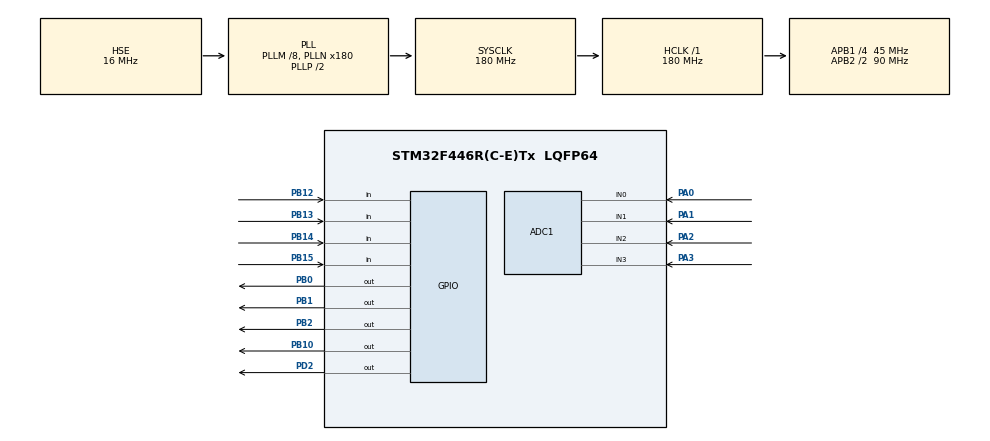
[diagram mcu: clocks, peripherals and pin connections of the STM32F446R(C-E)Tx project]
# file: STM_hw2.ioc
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ADC1.Channel-0\#ChannelRegularConversion=ADC_CHANNEL_0
ADC1.Channel-1\#ChannelRegularConversion=ADC_CHANNEL_1
ADC1.Channel-2\#ChannelRegularConversion=ADC_CHANNEL_2
ADC1.Channel-3\#ChannelRegularConversion=ADC_CHANNEL_3
ADC1.DMAContinuousRequests=ENABLE
ADC1.ExternalTrigConv=ADC_EXTERNALTRIGCONV_T8_TRGO
ADC1.NbrOfConversion=4
ADC1.NbrOfConversionFlag=1
ADC1.Rank-0\#ChannelRegularConversion=1
ADC1.Rank-1\#ChannelRegularConversion=2
ADC1.Rank-2\#ChannelRegularConversion=3
ADC1.Rank-3\#ChannelRegularConversion=4
ADC1.SamplingTime-0\#ChannelRegularConversion=ADC_SAMPLETIME_15CYCLES
ADC1.SamplingTime-1\#ChannelRegularConversion=ADC_SAMPLETIME_15CYCLES
ADC1.SamplingTime-2\#ChannelRegularConversion=ADC_SAMPLETIME_15CYCLES
ADC1.SamplingTime-3\#ChannelRegularConversion=ADC_SAMPLETIME_15CYCLES
ADC1.ScanConvMode=ENABLE
ADC1.master=1
Dma.ADC1.0.Direction=DMA_PERIPH_TO_MEMORY
Dma.ADC1.0.FIFOMode=DMA_FIFOMODE_DISABLE
Dma.ADC1.0.Instance=DMA2_Stream0
Dma.ADC1.0.MemDataAlignment=DMA_MDATAALIGN_WORD
Dma.ADC1.0.MemInc=DMA_MINC_ENABLE
Dma.ADC1.0.Mode=DMA_CIRCULAR
Dma.ADC1.0.PeriphDataAlignment=DMA_PDATAALIGN_WORD
Dma.ADC1.0.PeriphInc=DMA_PINC_DISABLE
Dma.ADC1.0.Priority=DMA_PRIORITY_LOW
Dma.Request0=ADC1
Mcu.Family=STM32F4
Mcu.Name=STM32F446R(C-E)Tx
Mcu.Package=LQFP64
NVIC.ADC_IRQn=true\:0\:0\:false\:false\:true\:true\:true\:true
NVIC.DMA2_Stream0_IRQn=true\:0\:0\:false\:false\:true\:false\:true\:true
NVIC.PriorityGroup=NVIC_PRIORITYGROUP_4
NVIC.TIM8_UP_TIM13_IRQn=true\:0\:0\:false\:false\:true\:true\:true\:true
PA0-WKUP.Signal=ADCx_IN0
PA1.Signal=ADCx_IN1
PA13.Mode=Serial_Wire
PA13.Signal=SYS_JTMS-SWDIO
PA14.Mode=Serial_Wire
PA14.Signal=SYS_JTCK-SWCLK
PA2.Signal=ADCx_IN2
PA3.Signal=ADCx_IN3
PB0.Signal=GPIO_Output
PB1.Signal=GPIO_Output
PB10.Signal=GPIO_Output
PB12.Signal=GPIO_Input
PB13.Signal=GPIO_Input
PB14.Signal=GPIO_Input
PB15.Signal=GPIO_Input
PB2.Signal=GPIO_Output
PD2.Signal=GPIO_Output
PH0-OSC_IN.Mode=HSE-External-Oscillator
PH0-OSC_IN.Signal=RCC_OSC_IN
PH1-OSC_OUT.Mode=HSE-External-Oscillator
PH1-OSC_OUT.Signal=RCC_OSC_OUT
ProjectManager.HeapSize=0x200
ProjectManager.StackSize=0x400
ProjectManager.TargetToolchain=STM32CubeIDE
RCC.AHBFreq_Value=180000000
RCC.APB1CLKDivider=RCC_HCLK_DIV4
RCC.APB1Freq_Value=45000000
RCC.APB1TimFreq_Value=90000000
RCC.APB2CLKDivider=RCC_HCLK_DIV2
RCC.APB2Freq_Value=90000000
RCC.APB2TimFreq_Value=180000000
RCC.CortexFreq_Value=180000000
RCC.HCLKFreq_Value=180000000
RCC.HSE_VALUE=16000000
RCC.PLLM=8
RCC.PLLN=180
RCC.PLLSourceVirtual=RCC_PLLSOURCE_HSE
RCC.SYSCLKFreq_VALUE=180000000
RCC.SYSCLKSource=RCC_SYSCLKSOURCE_PLLCLK
RCC.USBFreq_Value=180000000
RCC.VCOOutputFreq_Value=360000000
SH.ADCx_IN0.0=ADC1_IN0,IN0
SH.ADCx_IN1.0=ADC1_IN1,IN1
SH.ADCx_IN2.0=ADC1_IN2,IN2
SH.ADCx_IN3.0=ADC1_IN3,IN3
TIM8.Period=10000-1
TIM8.Prescaler=180-1
TIM8.TIM_MasterOutputTrigger=TIM_TRGO_UPDATE
VP_TIM8_VS_ClockSourceINT.Mode=Internal
board=custom

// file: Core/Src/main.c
/* USER CODE BEGIN Header */
/**
  ******************************************************************************
  * @file           : main.c
  * @brief          : Main program body
  ******************************************************************************
  * @attention
  *
  * Copyright (c) 2026 STMicroelectronics.
  * All rights reserved.
  *
  * This software is licensed under terms that can be found in the LICENSE file
  * in the root directory of this software component.
  * If no LICENSE file comes with this software, it is provided AS-IS.
  *
  ******************************************************************************
  */
/* USER CODE END Header */
#include "main.h"

/* USER CODE BEGIN Includes */
#include "hw2.h"
/* USER CODE END Includes */

ADC_HandleTypeDef hadc1;
DMA_HandleTypeDef hdma_adc1;

TIM_HandleTypeDef htim8;

/* USER CODE BEGIN PV */
uint32_t adc1_buffer[4] = {0, };
volatile uint8_t adc_updated_flag = 0;
/* USER CODE END PV */

void SystemClock_Config(void);
static void MX_GPIO_Init(void);
static void MX_DMA_Init(void);
static void MX_ADC1_Init(void);
static void MX_TIM8_Init(void);

int main(void)
{

  /* MCU Configuration--------------------------------------------------------*/

  /* Reset of all peripherals, Initializes the Flash interface and the Systick. */
  HAL_Init();

  /* Configure the system clock */
  SystemClock_Config();

  /* Initialize all configured peripherals */
  MX_GPIO_Init();
  MX_DMA_Init();
  MX_ADC1_Init();
  MX_TIM8_Init();
  /* USER CODE BEGIN 2 */
  HAL_TIM_Base_Start_IT(&htim8);
  HAL_ADC_Start_DMA(&hadc1, adc1_buffer, 4);
  hw2_init();
  /* USER CODE END 2 */

  /* Infinite loop */
  while (1)
  {

    /* USER CODE BEGIN 3 */
    hw2_loop();
  }
  /* USER CODE END 3 */
}

void SystemClock_Config(void)
{
  RCC_OscInitTypeDef RCC_OscInitStruct = {0};
  RCC_ClkInitTypeDef RCC_ClkInitStruct = {0};

  /** Configure the main internal regulator output voltage
  */
  __HAL_RCC_PWR_CLK_ENABLE();
  __HAL_PWR_VOLTAGESCALING_CONFIG(PWR_REGULATOR_VOLTAGE_SCALE1);

  /** Initializes the RCC Oscillators according to the specified parameters
  * in the RCC_OscInitTypeDef structure.
  */
  RCC_OscInitStruct.OscillatorType = RCC_OSCILLATORTYPE_HSE;
  RCC_OscInitStruct.HSEState = RCC_HSE_ON;
  RCC_OscInitStruct.PLL.PLLState = RCC_PLL_ON;
  RCC_OscInitStruct.PLL.PLLSource = RCC_PLLSOURCE_HSE;
  RCC_OscInitStruct.PLL.PLLM = 8;
  RCC_OscInitStruct.PLL.PLLN = 180;
  RCC_OscInitStruct.PLL.PLLP = RCC_PLLP_DIV2;
  RCC_OscInitStruct.PLL.PLLQ = 2;
  RCC_OscInitStruct.PLL.PLLR = 2;
  if (HAL_RCC_OscConfig(&RCC_OscInitStruct) != HAL_OK)
  {
    Error_Handler();
  }

  /** Activate the Over-Drive mode
  */
  if (HAL_PWREx_EnableOverDrive() != HAL_OK)
  {
    Error_Handler();
  }

  /** Initializes the CPU, AHB and APB buses clocks
  */
  RCC_ClkInitStruct.ClockType = RCC_CLOCKTYPE_HCLK|RCC_CLOCKTYPE_SYSCLK
                              |RCC_CLOCKTYPE_PCLK1|RCC_CLOCKTYPE_PCLK2;
  RCC_ClkInitStruct.SYSCLKSource = RCC_SYSCLKSOURCE_PLLCLK;
  RCC_ClkInitStruct.AHBCLKDivider = RCC_SYSCLK_DIV1;
  RCC_ClkInitStruct.APB1CLKDivider = RCC_HCLK_DIV4;
  RCC_ClkInitStruct.APB2CLKDivider = RCC_HCLK_DIV2;

  if (HAL_RCC_ClockConfig(&RCC_ClkInitStruct, FLASH_LATENCY_5) != HAL_OK)
  {
    Error_Handler();
  }
}

static void MX_ADC1_Init(void)
{

  ADC_ChannelConfTypeDef sConfig = {0};

  /** Configure the global features of the ADC (Clock, Resolution, Data Alignment and number of conversion)
  */
  hadc1.Instance = ADC1;
  hadc1.Init.ClockPrescaler = ADC_CLOCK_SYNC_PCLK_DIV4;
  hadc1.Init.Resolution = ADC_RESOLUTION_12B;
  hadc1.Init.ScanConvMode = ENABLE;
  hadc1.Init.ContinuousConvMode = DISABLE;
  hadc1.Init.DiscontinuousConvMode = DISABLE;
  hadc1.Init.ExternalTrigConvEdge = ADC_EXTERNALTRIGCONVEDGE_RISING;
  hadc1.Init.ExternalTrigConv = ADC_EXTERNALTRIGCONV_T8_TRGO;
  hadc1.Init.DataAlign = ADC_DATAALIGN_RIGHT;
  hadc1.Init.NbrOfConversion = 4;
  hadc1.Init.DMAContinuousRequests = ENABLE;
  hadc1.Init.EOCSelection = ADC_EOC_SINGLE_CONV;
  if (HAL_ADC_Init(&hadc1) != HAL_OK)
  {
    Error_Handler();
  }

  /** Configure for the selected ADC regular channel its corresponding rank in the sequencer and its sample time.
  */
  sConfig.Channel = ADC_CHANNEL_0;
  sConfig.Rank = 1;
  sConfig.SamplingTime = ADC_SAMPLETIME_15CYCLES;
  if (HAL_ADC_ConfigChannel(&hadc1, &sConfig) != HAL_OK)
  {
    Error_Handler();
  }

  /** Configure for the selected ADC regular channel its corresponding rank in the sequencer and its sample time.
  */
  sConfig.Channel = ADC_CHANNEL_1;
  sConfig.Rank = 2;
  if (HAL_ADC_ConfigChannel(&hadc1, &sConfig) != HAL_OK)
  {
    Error_Handler();
  }

  /** Configure for the selected ADC regular channel its corresponding rank in the sequencer and its sample time.
  */
  sConfig.Channel = ADC_CHANNEL_2;
  sConfig.Rank = 3;
  if (HAL_ADC_ConfigChannel(&hadc1, &sConfig) != HAL_OK)
  {
    Error_Handler();
  }

  /** Configure for the selected ADC regular channel its corresponding rank in the sequencer and its sample time.
  */
  sConfig.Channel = ADC_CHANNEL_3;
  sConfig.Rank = 4;
  if (HAL_ADC_ConfigChannel(&hadc1, &sConfig) != HAL_OK)
  {
    Error_Handler();
  }

}

static void MX_TIM8_Init(void)
{

  TIM_ClockConfigTypeDef sClockSourceConfig = {0};
  TIM_MasterConfigTypeDef sMasterConfig = {0};

  htim8.Instance = TIM8;
  htim8.Init.Prescaler = 180-1;
  htim8.Init.CounterMode = TIM_COUNTERMODE_UP;
  htim8.Init.Period = 10000-1;
  htim8.Init.ClockDivision = TIM_CLOCKDIVISION_DIV1;
  htim8.Init.RepetitionCounter = 0;
  htim8.Init.AutoReloadPreload = TIM_AUTORELOAD_PRELOAD_DISABLE;
  if (HAL_TIM_Base_Init(&htim8) != HAL_OK)
  {
    Error_Handler();
  }
  sClockSourceConfig.ClockSource = TIM_CLOCKSOURCE_INTERNAL;
  if (HAL_TIM_ConfigClockSource(&htim8, &sClockSourceConfig) != HAL_OK)
  {
    Error_Handler();
  }
  sMasterConfig.MasterOutputTrigger = TIM_TRGO_UPDATE;
  sMasterConfig.MasterSlaveMode = TIM_MASTERSLAVEMODE_DISABLE;
  if (HAL_TIMEx_MasterConfigSynchronization(&htim8, &sMasterConfig) != HAL_OK)
  {
    Error_Handler();
  }

}

static void MX_DMA_Init(void)
{

  /* DMA controller clock enable */
  __HAL_RCC_DMA2_CLK_ENABLE();

  /* DMA interrupt init */
  /* DMA2_Stream0_IRQn interrupt configuration */
  HAL_NVIC_SetPriority(DMA2_Stream0_IRQn, 0, 0);
  HAL_NVIC_EnableIRQ(DMA2_Stream0_IRQn);

}

static void MX_GPIO_Init(void)
{
  GPIO_InitTypeDef GPIO_InitStruct = {0};

  /* GPIO Ports Clock Enable */
  __HAL_RCC_GPIOH_CLK_ENABLE();
  __HAL_RCC_GPIOA_CLK_ENABLE();
  __HAL_RCC_GPIOB_CLK_ENABLE();
  __HAL_RCC_GPIOD_CLK_ENABLE();

  /*Configure GPIO pin Output Level */
  HAL_GPIO_WritePin(GPIOB, GPIO_PIN_0|GPIO_PIN_1|GPIO_PIN_2|GPIO_PIN_10, GPIO_PIN_RESET);

  /*Configure GPIO pin Output Level */
  HAL_GPIO_WritePin(GPIOD, GPIO_PIN_2, GPIO_PIN_RESET);

  /*Configure GPIO pins : PB0 PB1 PB2 PB10 */
  GPIO_InitStruct.Pin = GPIO_PIN_0|GPIO_PIN_1|GPIO_PIN_2|GPIO_PIN_10;
  GPIO_InitStruct.Mode = GPIO_MODE_OUTPUT_PP;
  GPIO_InitStruct.Pull = GPIO_NOPULL;
  GPIO_InitStruct.Speed = GPIO_SPEED_FREQ_LOW;
  HAL_GPIO_Init(GPIOB, &GPIO_InitStruct);

  /*Configure GPIO pins : PB12 PB13 PB14 PB15 */
  GPIO_InitStruct.Pin = GPIO_PIN_12|GPIO_PIN_13|GPIO_PIN_14|GPIO_PIN_15;
  GPIO_InitStruct.Mode = GPIO_MODE_INPUT;
  GPIO_InitStruct.Pull = GPIO_NOPULL;
  HAL_GPIO_Init(GPIOB, &GPIO_InitStruct);

  /*Configure GPIO pin : PD2 */
  GPIO_InitStruct.Pin = GPIO_PIN_2;
  GPIO_InitStruct.Mode = GPIO_MODE_OUTPUT_PP;
  GPIO_InitStruct.Pull = GPIO_NOPULL;
  GPIO_InitStruct.Speed = GPIO_SPEED_FREQ_LOW;
  HAL_GPIO_Init(GPIOD, &GPIO_InitStruct);

}

/* USER CODE BEGIN 4 */
void HAL_ADC_ConvCpltCallback(ADC_HandleTypeDef* hadc)
{
  if (hadc->Instance == hadc1.Instance) {
    adc_updated_flag = 1; // Callback이 호출되었다는 표시만 남김

    // 여기서 buffer 값을 다른 변수로 복사하거나
    // 필터를 적용하고 싶으면 이 안에서 처리함.
  }
}
/* USER CODE END 4 */

void Error_Handler(void)
{
  __disable_irq();
  while (1)
  {
  }
}
